# shearwater register map
Vendor: RedShift Labs; Series: IMU; File version: 0.3
Address unit: 32 bits
Registers are 32-bit, read-write, reset 0x0 unless marked. A register's access mark holds for its fields unless they carry their own. Offsets are from the block's base; [hi:lo] are bit positions; {n}, {i} and the like mark numbered series; 'fields as' and 'values as' point back to an identical list.

## MAIN_REGISTER_MAP — Fusion Configuration Registers for the shearwater board
Base 0x00000000
? CREG_COM_SETTINGS — The CREG_COM_SETTINGS register is used to set the boards serial port baud rate and to enable (disable) the automatic transmission of sensor data and estimated states (telemetry).
  [31:28] BAUD_RATE — Sets the baud rate of the boards main serial port:
    0=Baud rate: 9600; 1=Baud rate: 14400; 2=Baud rate: 19200; 3=Baud rate: 38400; 4=Baud rate: 57600; 5=Baud rate: 115200; 6=Baud rate: 128000; 7=Baud rate: 153600; 8=Baud rate: 230400; 9=Baud rate: 256000; 10=Baud rate: 460800; 11=Baud rate: 921600
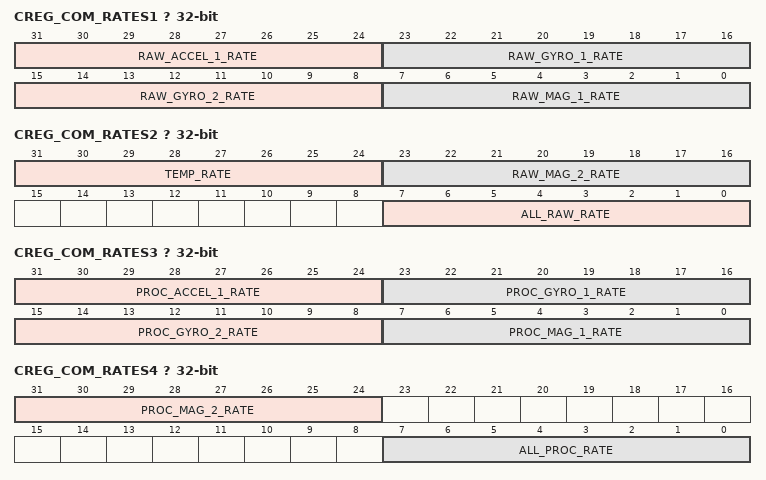
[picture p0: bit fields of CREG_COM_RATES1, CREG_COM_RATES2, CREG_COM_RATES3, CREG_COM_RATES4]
? CREG_COM_RATES1 — The CREG_COM_RATES1 register sets desired telemetry transmission rates in Hz for raw accelerometer 1, gyro 1, gyro 2 and magnetometer 1 data. If the specified rate is 0, then no data is transmitted.
  [31:24] RAW_ACCEL_1_RATE — Specifies the desired raw accelerometer 1 data broadcast rate in Hz. The data is stored as an unsigned 8-bit integer, yielding a maximum rate of 255 Hz.
  [23:16] RAW_GYRO_1_RATE — Specifies the desired raw gyro 1 data broadcast rate in Hz. The data is stored as an unsigned 8-bit integer, yielding a maximum rate of 255 Hz
  [15:8] RAW_GYRO_2_RATE — Specifies the desired raw gyro 2 data broadcast rate in Hz. The data is stored as an unsigned 8-bit integer, yielding a maximum rate of 255 Hz.
  [7:0] RAW_MAG_1_RATE — Specifies the desired raw magnetometer 1 data broadcast rate in Hz. The data is stored as an unsigned 8-bit integer, yielding a maximum rate of 255 Hz.
? CREG_COM_RATES2 — The CREG_COM_RATES2 register sets desired telemetry transmission rates for the magnetometer 2, all raw data, and temperature data rate. The ALL_RAW_RATE setting has higher priority over the individual raw sensor data settings, i.e. whenever this bitfield is set, then the individual raw sensor settings are ignored and not used. If the specified rate is 0, then no data is transmitted.
  [31:24] TEMP_RATE — Specifies the desired broadcast rate for temperature data. The data is stored as an unsigned 8-bit integer, yielding a maximum rate of 255 Hz.
  [23:16] RAW_MAG_2_RATE — Specifies the desired raw magnetometer 2 data broadcast rate in Hz. The data is stored as an unsigned 8-bit integer, yielding a maximum rate of 255 Hz.
  [7:0] ALL_RAW_RATE — Specifies the desired broadcast rate for all raw sensor data. If set, this overrides the broadcast rate setting for individual raw data broadcast rates. The data is stored as an unsigned 8-bit integer, yielding a maximum rate of 255 Hz.
? CREG_COM_RATES3 — The CREG_COM_RATES3 register sets desired telemetry transmission rates for processed sensor data for the sensors: the accelerometer 1, gyro 1, gyro 2, and magnetometer 1. If the specified rate is 0, then no data is transmitted.
  [31:24] PROC_ACCEL_1_RATE — Specifies the desired broadcast rate for processed accelerometer 1 data. The data is stored as an unsigned 8-bit integer, yielding a maximum rate of 255 Hz.
  [23:16] PROC_GYRO_1_RATE — Specifies the desired broadcast rate for processed rate gyro 1 data. The data is stored as an unsigned 8-bit integer, yielding a maximum rate of 255 Hz.
  [15:8] PROC_GYRO_2_RATE — Specifies the desired broadcast rate for processed processed rate gyro 2 data. The data is stored as an unsigned 8-bit integer, yielding a maximum rate of 255 Hz.
  [7:0] PROC_MAG_1_RATE — Specifies the desired broadcast rate for processed magnetometer 1 data. The data is stored as an unsigned 8-bit integer, yielding a maximum rate of 255 Hz.
? CREG_COM_RATES4 — The CREG_COM_RATES4 register defines the desired telemetry transmission rates for the processed data for the magnetometer 2, and for all processed data. The ALL_PROC_RATE setting has higher priority over the individual processed sensor data settings, i.e. whenever this bitfield is set, then the individual processed sensor transmission rate settings are ignored and not used. If the specified rate is 0, then no data is transmitted.
  [31:24] PROC_MAG_2_RATE — Specifies the desired broadcast rate for processed magnetometer 2 data. The data is stored as an unsigned 8-bit integer, yielding a maximum rate of 255 Hz.
  [7:0] ALL_PROC_RATE — Specifies the desired broadcast rate for raw all processed sensor data. If set, this overrides the broadcast rate setting for individual processed data broadcast rates. The data is stored as an unsigned 8-bit integer, yielding a maximum rate of 255 Hz.
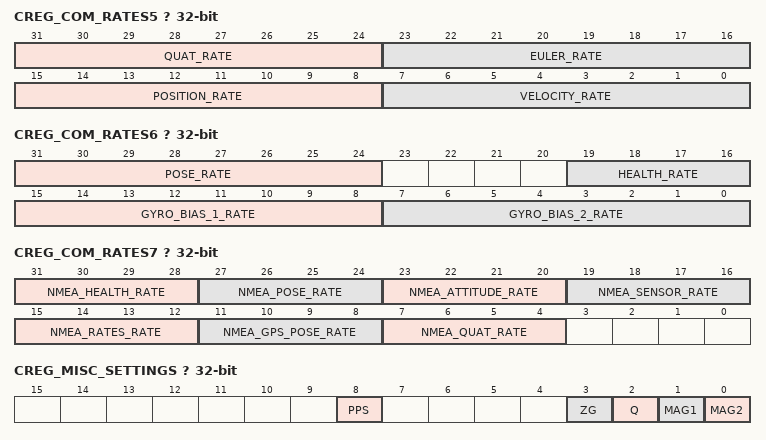
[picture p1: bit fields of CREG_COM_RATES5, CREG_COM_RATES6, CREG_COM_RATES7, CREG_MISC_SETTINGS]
? CREG_COM_RATES5 — The CREG_COM_RATES5 register sets desired telemetry transmission rates for quaternions, Euler Angles, position, and velocity estimates. If the specified rate is 0, then no data is transmitted.
  [31:24] QUAT_RATE — Specifies the desired broadcast rate for quaternion data. The data is stored as an unsigned 8-bit integer, yielding a maximum rate of 255 Hz.
  [23:16] EULER_RATE — Specifies the desired broadcast rate for Euler Angle data. The data is stored as an unsigned 8-bit integer, yielding a maximum rate of 255 Hz.
  [15:8] POSITION_RATE — Specifies the desired broadcast rate position. The data is stored as an unsigned 8-bit integer, yielding a maximum rate of 255 Hz.
  [7:0] VELOCITY_RATE — Specifies the desired broadcast rate for velocity. The data is stored as an unsigned 8-bit integer, yielding a maximum rate of 255 Hz.
? CREG_COM_RATES6 — The CREG_COM_RATES6 register sets desired telemetry transmission rates for pose (Euler/position packet), health, and gyro bias estimates for the gyro 1 and gyro 2. If the specified rate is 0, then no data is transmitted.
  [31:24] POSE_RATE — Specifies the desired broadcast rate for pose (Euler Angle and position) data. The data is stored as an unsigned 8-bit integer, yielding a maximum rate of 255 Hz.
  [19:16] HEALTH_RATE — Specifies the desired broadcast rate for the sensor health packet.
    0=Packet frequency: OFF; 1=0_125 (Packet frequency: 0.125 Hz); 2=0_25 (Packet frequency: 0.25 Hz); 3=0_5 (Packet frequency: 0.5 Hz); 4=Packet frequency: 1 Hz; 5=Packet frequency: 2 Hz; 6=Packet frequency: 4 Hz
  [15:8] GYRO_BIAS_1_RATE — Specifies the desired broadcast rate for gyro 1 bias estimates. The data is stored as an unsigned 8-bit integer, yielding a maximum rate of 255 Hz.
  [7:0] GYRO_BIAS_2_RATE — Specifies the desired broadcast rate for gyro 2 bias estimates. The data is stored as an unsigned 8-bit integer, yielding a maximum rate of 255 Hz.
? CREG_COM_RATES7 — The CREG_COM_RATES7 register sets desired telemetry transmission rates in Hz for NMEA packets.
  [all] fields
    0=Packet frequency: OFF; 1=Packet frequency: 1 Hz; 2=Packet frequency: 2 Hz; 3=Packet frequency: 4 Hz; 4=Packet frequency: 5 Hz; 5=Packet frequency: 10 Hz; 6=Packet frequency: 15 Hz; 7=Packet frequency: 20 Hz; 8=Packet frequency: 30 Hz; 9=Packet frequency: 40 Hz; 10=Packet frequency: 50 Hz; 11=Packet frequency: 60 Hz; 12=Packet frequency: 70 Hz; 13=Packet frequency: 80 Hz; 14=Packet frequency: 90 Hz; 15=Packet frequency: 100 Hz
  [31:28] NMEA_HEALTH_RATE — Specifies the desired broadcast rate for Redshift Labs NMEA-style health packet.
  [27:24] NMEA_POSE_RATE — Specifies the desired broadcast rate for Redshift Labs NMEA-style pose (Euler Angle/position) packet.
  [23:20] NMEA_ATTITUDE_RATE — Specifies the desired broadcast rate for Redshift Labs NMEA-style attitude packet.
  [19:16] NMEA_SENSOR_RATE — Specifies the desired broadcast rate for Redshift Labs NMEA-style sensor data packet.
  [15:12] NMEA_RATES_RATE — Specifies the desired broadcast rate for Redshift Labs NMEA-style rate data packet.
  [11:8] NMEA_GPS_POSE_RATE — Specifies the desired broadcast rate for Redshift Labs NMEA-style GPS pose packet.
  [7:4] NMEA_QUAT_RATE — Specifies the desired broadcast rate for Redshift Labs NMEA-style quaternion packet.
? CREG_MISC_SETTINGS — This register contains miscellaneous filter and sensor control options.
  [8] PPS — If set, this bit causes the TX2 pin on the IO Expansion header to be used as the PPS input from an external GPS module. PPS pulses will then be used to synchronize the system clock to UTC time of day.
    0=PPS_OFF (TX2 not used as PPS input from GPS); 1=PPS_ON (TX2 used as PPS input from GPS)
  [3] ZG — If set, this bit causes the devicee to attempt to measure the rate gyro bias on startup. The sensor must be stationary on startup for this feature to work properly.
    0=ZG_OFF (NOT measure rate gyro bias on startup); 1=ZG_ON (Measure rate gyro bias on startup)
  [2] Q — If this bit is set, the sensor will run in quaternion mode instead of Euler Angle mode.
    0=EULER_MODE (The sensor will run in Euler Angle mode); 1=QUATERNION_MODE (The sensor will run in quaternion mode)
  [1] MAG1 — If set, the magnetometer 1 will be used in state updates.
    0=MAG1_NOT_IN_STATE (NOT use magnetometer 1 in state update); 1=MAG1_IN_STATE (Use magnetometer 1 in state update)
  [0] MAG2 — If set, the magnetometer 2 will be used in state updates.
    0=MAG2_NOT_IN_STATE (NOT use magnetometer 2 in state update); 1=MAG2_IN_STATE (Use magnetometer 2 in state update)
? CREG_GYRO_1_MEAS_RANGE — The CREG_GYRO_1_MEAS_RANGE register sets the desired measurement range for the gyro 1 sensor. If the rate is not set, then the default value of 2000 deg/s will be used as a measurement range.
  [1:0] MEAS_GYRO1 — Specifies the desired measurement range for the gyro 1 measurements.
    0=2000_dps (Measurement range: +- 2000 dps); 1=1000_dps (Measurement range: +- 1000 dps); 2=500_dps (Measurement range: +- 500 dps); 3=250_dps (Measurement range: +- 250 dps)
? CREG_GYRO_1_TRIM_X — This register sets the x-axis rate gyro 1 trim, which is used to add additional bias compensation for the rate gyros during calls to the ZERO_GYRO_BIAS command.
  [31:0] GYRO_1_TRIM_X — 32-bit IEEE Floating Point Value
? CREG_GYRO_1_TRIM_Y — This register sets the y-axis rate gyro 1 trim, which is used to add additional bias compensation for the rate gyros during calls to the ZERO_GYRO_BIAS command.
  [31:0] GYRO_1_TRIM_Y — 32-bit IEEE Floating Point Value
? CREG_GYRO_1_TRIM_Z — This register sets the z-axis rate gyro 1 trim, which is used to add additional bias compensation for the rate gyros during calls to the ZERO_GYRO_BIAS command.
  [31:0] GYRO_1_TRIM_Z — 32-bit IEEE Floating Point Value
? CREG_GYRO_2_MEAS_RANGE — The CREG_GYRO_2_MEAS_RANGE register sets the desired measurement range for the gyro 2 sensor. If the rate is not set, then the default value of 2000 deg/s will be used as a measurement range.
  [1:0] MEAS_GYRO2 — Specifies the desired measurement range for the gyro 2 measurements.
    values as CREG_GYRO_1_MEAS_RANGE.MEAS_GYRO1
? CREG_GYRO_2_TRIM_X — This register sets the x-axis rate gyro 2 trim, which is used to add additional bias compensation for the rate gyros during calls to the ZERO_GYRO_BIAS command.
  [31:0] GYRO_2_TRIM_X — 32-bit IEEE Floating Point Value
? CREG_GYRO_2_TRIM_Y — This register sets the y-axis rate gyro 2 trim, which is used to add additional bias compensation for the rate gyros during calls to the ZERO_GYRO_BIAS command.
  [31:0] GYRO_2_TRIM_Y — 32-bit IEEE Floating Point Value
? CREG_GYRO_2_TRIM_Z — This register sets the z-axis rate gyro 2 trim, which is used to add additional bias compensation for the rate gyros during calls to the ZERO_GYRO_BIAS command.
  [31:0] GYRO_2_TRIM_Z — 32-bit IEEE Floating Point Value
? CREG_MAG_1_CAL{i}_1 (i=1..3) — Row {i}, Column 1 of magnetometer 1 calibration matrix.
  [31:0] MAG_1_CAL{i}_1 — 32-bit IEEE Floating Point Value
? CREG_MAG_1_CAL{i}_2 (i=1..3) — Row {i}, Column 2 of magnetometer 1 calibration matrix.
  [31:0] MAG_1_CAL{i}_2 — 32-bit IEEE Floating Point Value
? CREG_MAG_1_CAL{i}_3 (i=1..3) — Row {i}, Column 3 of magnetometer 1 calibration matrix.
  [31:0] MAG_1_CAL{i}_3 — 32-bit IEEE Floating Point Value
? CREG_MAG_1_BIAS_X — This register stores a bias term for the magnetometer 1 x-axis for hard-iron calibration. This term can be computed by performing magnetometer calibration with the Redshift labs Serial Interface.
  [31:0] MAG_1_BIAS_X — 32-bit IEEE Floating Point Value
? CREG_MAG_1_BIAS_Y — This register stores a bias term for the magnetometer 1 y-axis for hard-iron calibration. This term can be computed by performing magnetometer calibration with the Redshift labs Serial Interface.
  [31:0] MAG_1_BIAS_Y — 32-bit IEEE Floating Point Value
? CREG_MAG_1_BIAS_Z — This register stores a bias term for the magnetometer 1 z-axis for hard-iron calibration. This term can be computed by performing magnetometer calibration with the Redshift labs Serial Interface.
  [31:0] MAG_1_BIAS_Z — 32-bit IEEE Floating Point Value
? CREG_MAG_2_CAL{i}_1 (i=1..3) — Row {i}, Column 1 of magnetometer 2 calibration matrix.
  [31:0] MAG_2_CAL{i}_1 — 32-bit IEEE Floating Point Value
? CREG_MAG_2_CAL{i}_2 (i=1..3) — Row {i}, Column 2 of magnetometer 2 calibration matrix.
  [31:0] MAG_2_CAL{i}_2 — 32-bit IEEE Floating Point Value
? CREG_MAG_2_CAL{i}_3 (i=1..3) — Row {i}, Column 3 of magnetometer 2 calibration matrix.
  [31:0] MAG_2_CAL{i}_3 — 32-bit IEEE Floating Point Value
? CREG_MAG_2_BIAS_X — This register stores a bias term for the magnetometer 2 x-axis for hard-iron calibration. This term can be computed by performing magnetometer calibration with the Redshift labs Serial Interface.
  [31:0] MAG_2_BIAS_X — 32-bit IEEE Floating Point Value
? CREG_MAG_2_BIAS_Y — This register stores a bias term for the magnetometer 2 y-axis for hard-iron calibration. This term can be computed by performing magnetometer calibration with the Redshift labs Serial Interface.
  [31:0] MAG_2_BIAS_Y — 32-bit IEEE Floating Point Value
? CREG_MAG_2_BIAS_Z — This register stores a bias term for the magnetometer 2 z-axis for hard-iron calibration. This term can be computed by performing magnetometer calibration with the Redshift labs Serial Interface.
  [31:0] MAG_2_BIAS_Z — 32-bit IEEE Floating Point Value
? CREG_ACCEL_1_MEAS_RANGE — The CREG_ACCEL_1_MEAS_RANGE register sets the desired measurement range for the accelerometer 1. If the rate is not set, then the default value of the +-2 g will be used as a measurement range.
  [1:0] MEAS_ACC1 — Specifies the desired measurement range for the accelerometer 1 measurements.
    0=2_g (Measurement range: +- 2 g); 1=4_g (Measurement range: +- 4 g); 2=8_g (Measurement range: +- 8 g); 3=16_g (Measurement range: +- 16 g)
? CREG_ACCEL_1_CAL{i}_1 (i=1..3) — Row {i}, Column 1 of accelerometer 1 calibration matrix.
  [31:0] ACCEL_1_CAL{i}_1 — 32-bit IEEE Floating Point Value
? CREG_ACCEL_1_CAL{i}_2 (i=1..3) — Row {i}, Column 2 of accelerometer 1 calibration matrix.
  [31:0] ACCEL_1_CAL{i}_2 — 32-bit IEEE Floating Point Value
? CREG_ACCEL_1_CAL{i}_3 (i=1..3) — Row {i}, Column 3 of accelerometer 1 calibration matrix.
  [31:0] ACCEL_1_CAL{i}_3 — 32-bit IEEE Floating Point Value
? CREG_ACCEL_1_BIAS_X — This register stores a bias term for the accelerometer 1 x-axis for bias calibration. This term can be computed by performing calibrate accelerometers command within the Redshift labs Serial Interface.
  [31:0] ACCEL_1_BIAS_X — 32-bit IEEE Floating Point Value
? CREG_ACCEL_1_BIAS_Y — This register stores a bias term for the accelerometer 1 y-axis for bias calibration. This term can be computed by performing calibrate accelerometers command within the Redshift labs Serial Interface.
  [31:0] ACCEL_1_BIAS_Y — 32-bit IEEE Floating Point Value
? CREG_ACCEL_1_BIAS_Z — This register stores a bias term for the accelerometer 1 z-axis for bias calibration. This term can be computed by performing calibrate accelerometers command within the Redshift labs Serial Interface.
  [31:0] ACCEL_1_BIAS_Z — 32-bit IEEE Floating Point Value
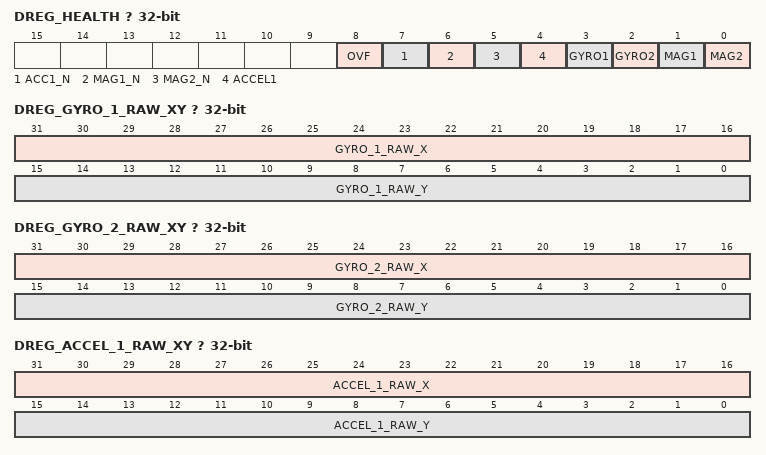
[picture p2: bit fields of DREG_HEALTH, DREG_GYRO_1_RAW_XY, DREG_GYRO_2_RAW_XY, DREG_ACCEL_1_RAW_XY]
? DREG_HEALTH ro — The health register reports the current status of the sensors on the board. Monitoring the health register is the easiest way to watch for other problems that could affect the behavior of the board, status of the sensors. The analogous to the health register, the status of the GPS signal can be monitored in the DREG_GPS_HEALTH
  [8] OVF — Overflow bit. This bit is set if the board is attempting to transmit data over the serial port faster than is allowed given the baud-rate. If this bit is set, reduce broadcast rates in the COM_RATES registers.
    0=OVF_OFF (No overflow registered); 1=OVF_ON (Overflow registered, reduce broadcast rates)
  [7] ACC1_N — This bit is set if the sensor detects that the norm of the accelerometer measurement is too far away from 1G to be used (i.e. during aggressive acceleration or high vibration).
    0=ACC1_N_OFF (No high acceleration / no high vibration detected); 1=ACC1_N_ON (High acceleration / high vibration detected)
  [6] MAG1_N — This bit is set if the sensor detects that the norm of the magnetometer measurement for the magnetometer 1 is too far away from 1.0 to be trusted. Usually indicates bad calibration, local field distortions, or both.
    0=MAG2_NORM_OK (Magnetometer 1 norm is OK); 1=MAG2_NORM_WARN (Magnetometer 1 norm is not OK)
  [5] MAG2_N — This bit is set if the sensor detects that the norm of the magnetometer measurement for the magnetometer 2 is too far away from 1.0 to be trusted. Usually indicates bad calibration, local field distortions, or both.
    0=MAG2_NORM_OK (Magnetometer 2 norm is OK); 1=MAG2_NORM_WARN (Magnetometer 2 norm is not OK)
  [4] ACCEL1 — This bit will be set if the accelerometer 1 fails to initialize on startup.
    0=ACCEL1_STARTUP_OK (Accelerometer 1 startup OK); 1=ACCEL1_STARTUP_ERR (Accelerometer 1 startup error)
  [3] GYRO1 — This bit will be set if the rate gyro 1 fails to initialize on startup.
    0=GYRO1_STARTUP_OK; 1=GYRO1_STARTUP_ERR (Gyro 1 startup error)
  [2] GYRO2 — This bit will be set if the rate gyro 2 fails to initialize on startup.
    0=GYRO2_STARTUP_OK; 1=GYRO2_STARTUP_ERR (Gyro 2 startup error)
  [1] MAG1 — This bit will be set if the magnetometer 1 fails to initialize on startup.
    0=MAG1_STARTUP_OK (Magnetometer 1 startup OK); 1=MAG1_STARTUP_ERR (Magnetometer 1 startup error)
  [0] MAG2 — This bit will be set if the magnetometer 2 fails to initialize on startup.
    0=MAG2_STARTUP_OK (Magnetometer 2 startup OK); 1=MAG2_STARTUP_ERR (Magnetometer 2 startup error)
? DREG_GYRO_1_RAW_XY ro — Contains raw X and Y axis rate gyro 1 data.
  [31:16] GYRO_1_RAW_X — Gyro X (2s complement 16-bit integer)
  [15:0] GYRO_1_RAW_Y — Gyro Y (2s complement 16-bit integer)
? DREG_GYRO_1_RAW_Z ro — Contains raw Z axis rate gyro 1 data.
  [31:16] GYRO_1_RAW_Z — Gyro Z (2s complement 16-bit integer)
? DREG_GYRO_1_RAW_TIME ro — Contains time at which the last rate gyro 1 data was acquired.
  [31:0] GYRO_1_RAW_TIME — 32-bit IEEE Floating Point Value
? DREG_GYRO_2_RAW_XY ro — Contains raw X and Y axis rate gyro 2 data.
  [31:16] GYRO_2_RAW_X — Gyro X (2s complement 16-bit integer)
  [15:0] GYRO_2_RAW_Y — Gyro Y (2s complement 16-bit integer)
? DREG_GYRO_2_RAW_Z ro — Contains raw Z axis rate gyro 2 data.
  [31:16] GYRO_2_RAW_Z — Gyro Z (2s complement 16-bit integer)
? DREG_GYRO_2_RAW_TIME ro — Contains time at which the last rate gyro 2 data was acquired.
  [31:0] GYRO_2_RAW_TIME — 32-bit IEEE Floating Point Value
? DREG_ACCEL_1_RAW_XY ro — Contains raw X and Y axis accelerometer 1 data.
  [31:16] ACCEL_1_RAW_X — Accel X (2s complement 16-bit integer)
  [15:0] ACCEL_1_RAW_Y — Accel Y (2s complement 16-bit integer)
? DREG_ACCEL_1_RAW_Z ro — Contains raw Z axis accelerometer 1 data.
  [31:16] ACCEL_1_RAW_Z — Accel Z (2s complement 16-bit integer)
? DREG_ACCEL_1_RAW_TIME ro — Contains time at which the last raw data sample for the accelerometer 1 was acquired.
  [31:0] ACCEL_1_RAW_TIME — 32-bit IEEE Floating Point Value
? DREG_MAG_1_RAW_X ro — Contains raw x axis magnetometer 1 data.
  [31:0] MAG_1_RAW_X — 32-bit signed integer value
? DREG_MAG_1_RAW_Y ro — Contains raw y axis magnetometer 1 data.
  [31:0] MAG_1_RAW_Y — 32-bit signed integer value
? DREG_MAG_1_RAW_Z ro — Contains raw z axis magnetometer 1 data.
  [31:0] MAG_1_RAW_Z — 32-bit signed integer value
? DREG_MAG_1_RAW_TIME ro — Contains time at which the last magnetometer data from the magnetometer 1 was acquired.
  [31:0] MAG_1_RAW_TIME — 32-bit IEEE Floating Point Value
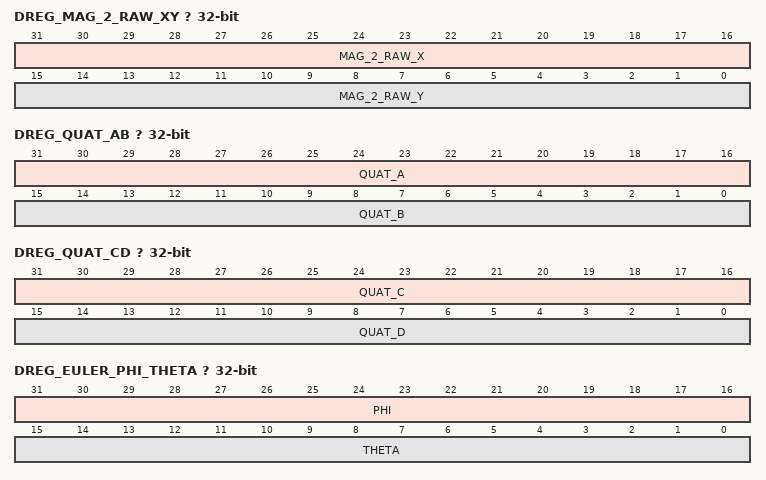
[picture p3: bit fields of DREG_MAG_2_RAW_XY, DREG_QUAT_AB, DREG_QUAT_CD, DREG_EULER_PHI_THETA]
? DREG_MAG_2_RAW_XY ro — Contains raw X and Y axis magnetometer 2 data.
  [31:16] MAG_2_RAW_X — Magnetometer X (2s complement 16-bit integer)
  [15:0] MAG_2_RAW_Y — Magnetometer Y (2s complement 16-bit integer)
? DREG_MAG_2_RAW_Z ro — Contains raw Z axis magnetometer 2 data.
  [31:16] MAG_2_RAW_Z — Magnetometer Z (2s complement 16-bit integer)
? DREG_MAG_2_RAW_TIME ro — Contains time at which the last magnetometer data from the magnetometer 2 was acquired.
  [31:0] MAG_2_RAW_TIME — 32-bit IEEE Floating Point Value
? DREG_TEMPERATURE ro — Contains the temperature output of the onboard temperature sensor.
  [31:0] TEMPERATURE — Temperature in degrees Celcius (32-bit IEEE Floating Point)
? DREG_TEMPERATURE_TIME ro — Contains time at which the last temperature was acquired.
  [31:0] TEMPERATURE_TIME — 32-bit IEEE Floating Point Value
? DREG_GYRO_1_PROC_X ro — Contains the actual measured angular rate from the gyro 1 for the x axis in degrees/sec after calibration has been applied.
  [31:0] GYRO_1_PROC_X — Gyro X in degrees / sec (32-bit IEEE Floating Point Value)
? DREG_GYRO_1_PROC_Y ro — Contains the actual measured angular rate from the gyro 1 for the y axis in degrees/sec after calibration has been applied.
  [31:0] GYRO_1_PROC_Y — Gyro Y in degrees / sec (32-bit IEEE Floating Point Value)
? DREG_GYRO_1_PROC_Z ro — Contains the actual measured angular rate from the gyro 1 for the z axis in degrees/sec after calibration has been applied.
  [31:0] GYRO_1_PROC_Z — Gyro Z in degrees / sec (32-bit IEEE Floating Point Value)
? DREG_GYRO_1_PROC_TIME ro — Contains the time at which the last rate gyro data from the gyro 1 was measured.
  [31:0] GYRO_1_PROC_TIME — Gyro 1 time stamp (32-bit IEEE Floating Point Value)
? DREG_GYRO_2_PROC_X ro — Contains the actual measured angular rate from the gyro 2 for the x axis in degrees/sec after calibration has been applied.
  [31:0] GYRO_2_PROC_X — Gyro X in degrees / sec (32-bit IEEE Floating Point Value)
? DREG_GYRO_2_PROC_Y ro — Contains the actual measured angular rate from the gyro 2 for the y axis in degrees/sec after calibration has been applied.
  [31:0] GYRO_2_PROC_Y — Gyro Y in degrees / sec (32-bit IEEE Floating Point Value)
? DREG_GYRO_2_PROC_Z ro — Contains the actual measured angular rate from the gyro 2 for the z axis in degrees/sec after calibration has been applied.
  [31:0] GYRO_2_PROC_Z — Gyro Z in degrees / sec (32-bit IEEE Floating Point Value)
? DREG_GYRO_2_PROC_TIME ro — Contains the time at which the last rate gyro data from the gyro 2 was measured.
  [31:0] GYRO_2_PROC_TIME — Gyro 2 time stamp (32-bit IEEE Floating Point Value)
? DREG_ACCEL_1_PROC_X ro — Contains the actual measured acceleration from the accelerometer 1 for the x axis in m/s2 after calibration has been applied.
  [31:0] ACCEL_1_PROC_X — Acceleration X in m/s2 (32-bit IEEE Floating Point Value)
? DREG_ACCEL_1_PROC_Y ro — Contains the actual measured acceleration from the accelerometer 1 for the y axis in m/s2 after calibration has been applied.
  [31:0] ACCEL_1_PROC_Y — Acceleration Y in m/s2 (32-bit IEEE Floating Point Value)
? DREG_ACCEL_1_PROC_Z ro — Contains the actual measured acceleration from the accelerometer 1 for the z axis in m/s2 after calibration has been applied.
  [31:0] ACCEL_1_PROC_Z — Acceleration Z in m/s2 (32-bit IEEE Floating Point Value)
? DREG_ACCEL_1_PROC_TIME ro — Contains the time at which the last acceleration data from the accelerometer 1 was measured.
  [31:0] ACCEL_1_PROC_TIME — Accelerometer 1 time stamp (32-bit IEEE Floating Point Value)
? DREG_MAG_1_PROC_X ro — Contains the actual measured magnetic field from the magnetometer 1 for the x axis in mT after calibration has been applied.
  [31:0] MAG_1_PROC_X — Magnetometer X in mT (32-bit IEEE Floating Point Value)
? DREG_MAG_1_PROC_Y ro — Contains the actual measured magnetic field from the magnetometer 1 for the y axis in mT after calibration has been applied.
  [31:0] MAG_1_PROC_Y — Magnetometer Y in mT (32-bit IEEE Floating Point Value)
? DREG_MAG_1_PROC_Z ro — Contains the actual measured magnetic field from the magnetometer 1 for the z axis in mT after calibration has been applied.
  [31:0] MAG_1_PROC_Z — Magnetometer Z in mT (32-bit IEEE Floating Point Value)
? DREG_MAG_1_NORM ro — Contains the L2-norm (magnetic norm) for the measured magnetic field from the magnetometer 1 computed over the calibrated values.
  [31:0] MAG_1_NORM — Magnetic norm (32-bit IEEE Floating Point Value)
? DREG_MAG_1_PROC_TIME ro — Contains the time stamp at which the calibrated magnetometer 1 data was acquired.
  [31:0] MAG_1_PROC_TIME — Magnetometer 1 time stamp (32-bit IEEE Floating Point Value)
? DREG_MAG_2_PROC_X ro — Contains the actual measured magnetic field from the magnetometer 2 for the x axis in mT after calibration has been applied.
  [31:0] MAG_2_PROC_X — Magnetometer X in mT (32-bit IEEE Floating Point Value)
? DREG_MAG_2_PROC_Y ro — Contains the actual measured magnetic field from the magnetometer 2 for the y axis in mT after calibration has been applied.
  [31:0] MAG_2_PROC_Y — Magnetometer Y in mT (32-bit IEEE Floating Point Value)
? DREG_MAG_2_PROC_Z ro — Contains the actual measured magnetic field from the magnetometer 2 for the z axis in mT after calibration has been applied.
  [31:0] MAG_2_PROC_Z — Magnetometer Z in mT (32-bit IEEE Floating Point Value)
? DREG_MAG_2_NORM ro — Contains the L2-norm (magnetic norm) for the measured magnetic field from the magnetometer 2 computed over the calibrated values.
  [31:0] MAG_2_NORM — Magnetic norm (32-bit IEEE Floating Point Value)
? DREG_MAG_2_PROC_TIME ro — Contains the time stamp at which the calibrated magnetometer 2 data was acquired.
  [31:0] MAG_2_PROC_TIME — Magnetometer 2 time stamp (32-bit IEEE Floating Point Value)
? DREG_QUAT_AB ro — Contains the first two components (a and b) of the estimated quaternion attitude.
  [31:16] QUAT_A — First quaternion component. Stored as a 16-bit signed integer. To get the actual value, divide by 29789.09091.
  [15:0] QUAT_B — Second quaternion component. Stored as a 16-bit signed integer. To get the actual value, divide by 29789.09091.
? DREG_QUAT_CD ro — Contains the second two components (c and d) of the estimated quaternion attitude.
  [31:16] QUAT_C — Third quaternion component. Stored as a 16-bit signed integer. To get the actual value, divide by 29789.09091.
  [15:0] QUAT_D — Fourth quaternion component. Stored as a 16-bit signed integer. To get the actual value, divide by 29789.09091.
? DREG_QUAT_TIME ro — Contains the time that the quaternion attitude was estimated.
  [31:0] QUAT_TIME — Quaternion time (32-bit IEEE Floating Point Value)
? DREG_EULER_PHI_THETA ro — Contains the pitch and roll angle estimates.
  [31:16] PHI — Roll angle. Stored as a 16-bit signed integer. To get the actual value, divide by 91.02222.
  [15:0] THETA — Pitch angle. Stored as a 16-bit signed integer. To get the actual value, divide by 91.02222.
? DREG_EULER_PSI ro — Contains the yaw angle estimate.
  [31:16] PSI — Yaw angle. Stored as a 16-bit signed integer. To get the actual value, divide by 91.02222.
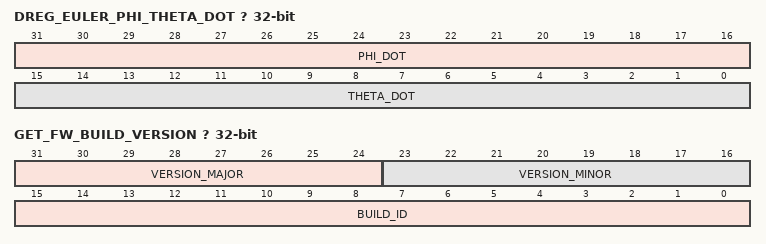
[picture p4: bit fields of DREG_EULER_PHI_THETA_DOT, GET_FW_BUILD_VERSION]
? DREG_EULER_PHI_THETA_DOT ro — Contains the pitch and roll rate estimates.
  [31:16] PHI_DOT — Roll rate. Stored as a 16-bit signed integer. To get the actual value, divide by 16.0.
  [15:0] THETA_DOT — Pitch rate. Stored as a 16-bit signed integer. To get the actual value, divide by 16.0.
? DREG_EULER_PSI_DOT ro — Contains the yaw rate estimate.
  [31:16] PSI_DOT — Yaw rate. Stored as a 16-bit signed integer. To get the actual value, divide by 16.0.
? DREG_EULER_TIME ro — Contains the time that the Euler Angles were estimated.
  [31:0] EULER_TIME — Euler time (32-bit IEEE Floating Point Value)
? DREG_POSITION_NORTH ro — Contains the measured north position in meters from the latitude specified in CREG_HOME_NORTH.
  [31:0] POSITION_NORTH — North Position (32-bit IEEE Floating Point Value)
? DREG_POSITION_EAST ro — Contains the measured east position in meters from the longitude specified in CREG_HOME_EAST.
  [31:0] POSITION_EAST — East Position (32-bit IEEE Floating Point Value)
? DREG_POSITION_UP ro — Contains the measured altitude in meters from the altitude specified in CREG_HOME_UP.
  [31:0] POSITION_UP — Altitude (32-bit IEEE Floating Point Value)
? DREG_POSITION_TIME ro — Contains the time at which the position was acquired.
  [31:0] POSITION_TIME — Position Time (32-bit IEEE Floating Point Value)
? DREG_VELOCITY_NORTH ro — Contains the measured north velocity in m/s.
  [31:0] VELOCITY_NORTH — North Velocity (32-bit IEEE Floating Point Value)
? DREG_VELOCITY_EAST ro — Contains the measured east velocity in m/s.
  [31:0] VELOCITY_EAST — East Velocity (32-bit IEEE Floating Point Value)
? DREG_VELOCITY_UP ro — Contains the measured altitude velocity in m/s.
  [31:0] VELOCITY_UP — Altitude Velocity (32-bit IEEE Floating Point Value)
? DREG_VELOCITY_TIME ro — Contains the time at which the velocity was measured.
  [31:0] VELOCITY_TIME — Velocity time (32-bit IEEE Floating Point Value)
? DREG_GYRO_1_BIAS_X ro — Contains the estimated x-axis bias for the gyro 1 in degrees/s.
  [31:0] GYRO_1_BIAS_X — Gyro 1 bias X (32-bit IEEE Floating Point Value)
? DREG_GYRO_1_BIAS_Y ro — Contains the estimated y-axis bias for the gyro 1 in degrees/s.
  [31:0] GYRO_1_BIAS_Y — Gyro 1 bias Y (32-bit IEEE Floating Point Value)
? DREG_GYRO_1_BIAS_Z ro — Contains the estimated z-axis bias for the gyro 1 in degrees/s.
  [31:0] GYRO_1_BIAS_Z — Gyro 1 bias Z (32-bit IEEE Floating Point Value)
? DREG_GYRO_2_BIAS_X ro — Contains the estimated x-axis bias for the gyro 2 in degrees/s.
  [31:0] GYRO_2_BIAS_X — Gyro 2 bias X (32-bit IEEE Floating Point Value)
? DREG_GYRO_2_BIAS_Y ro — Contains the estimated y-axis bias for the gyro 2 in degrees/s.
  [31:0] GYRO_2_BIAS_Y — Gyro 2 bias Y (32-bit IEEE Floating Point Value)
? DREG_GYRO_2_BIAS_Z ro — Contains the estimated z-axis bias for the gyro 2 in degrees/s.
  [31:0] GYRO_2_BIAS_Z — Gyro 2 bias Z (32-bit IEEE Floating Point Value)
? GET_FW_BUILD_ID ro — Firmware build identification string: a four byte ASCII character sequence which corresponds to a firmware series.
  [31:0] FW_BUILD_ID — Firmware Build ID string
? GET_FW_BUILD_VERSION ro — Firmware build version provides the unique identifier of the firmware programmed in the board. A response is four bytes long and identifies major and minor build version, and the build number.
  [31:24] VERSION_MAJOR — 8-bit unsigned integer major version number
  [23:16] VERSION_MINOR — 8-bit unsigned integer minor version number
  [15:0] BUILD_ID — 16-bit unsigned integer build ID number
? FLASH_COMMIT wo — Causes the board to write all configuration settings to FLASH so that are stored in the non-volatile memory and remain when the power is cycled.
  [1:0] FLASH_COMMIT_BIT
? RESET_TO_FACTORY wo — Causes the board to load default factory settings.
  [1:0] RESET_TO_FACTORY_BIT
? ZERO_GYROS wo — Causes the board to measure the gyro outputs and set the output trim registers to compensate for any non-zero bias. The board should be kept stationary while the zero operation is underway.
  [1:0] ZERO_GYROS_BIT
? SET_HOME_POSITION wo — Sets the current GPS latitude, longitude, and altitude as the home position. All future positions will be referenced to the current GPS position.
  [1:0] SET_HOME_POSITION_BIT
? SET_MAG_REFERENCE wo — Sets the current yaw heading position as north.
  [1:0] SET_MAG_REFERENCE_BIT — Set magnetometer reference bit
? CALIBRATE_ACCELEROMETERS wo — Reboots the board and performs a crude calibration on the accelerometers. Best performed on a flat surface.
  [1:0] CALIBRATE_ACCELEROMETERS_BIT
? RESET_FUSION wo — Resets the sensor fusion algorithm.
  [1:0] RESET_FUSION_BIT
? ENABLE_ZUPT wo — Enable zero velocity update.
  [1:0] ENABLE_ZUPT_BIT — Enable zero velocity update bit
? EULER_MODE wo — Enable as fusion output Euler angles only.
  [1:0] EULER_MODE_BIT — Fusion Euler mode bit
? QUATERNION_MODE wo — Enable as fusion output orientation quaternion only.
  [1:0] QUATERNION_MODE_BIT — Fusion quaternion mode bit
? ENABLE_RT_CALIBRATION wo — Starts RT calibration of the board.
  [1:0] ENABLE_RT_CALIBRATION_BIT — RT calibration bit
? EN_MAG_ANOMALY_DETECTION wo — Enables algorithm for anomaly detection.
  [1:0] EN_MAG_ANOMALY_DETECTION_BIT — Magnetic field anomaly detection bit
? RUN_SELF_TESTS wo — Starts built-in self tests.
  [1:0] RUN_SELF_TESTS_BIT
? ENABLE_EXTERNAL_EVENT wo — TODO: add description
  [1:0] ENABLE_EXTERNAL_EVENT_BIT
? ENABLE_GNNS_FUSION wo — TODO: add description
  [1:0] ENABLE_GNNS_FUSION_BIT — Enable GNSS fusion bit
? ENABLE_USR_EULER_OUTPUT wo — TODO: add description
  [1:0] ENABLE_USR_EULER_OUTPUT_BIT — Enable user Euler output bit
? ENABLE_DEAD_RECKONING wo — TODO: add description
  [1:0] ENABLE_DEAD_RECKONING_BIT
? ENABLE_HEAVE_SWAY_SURGE wo — TODO: add description
  [1:0] ENABLE_HEAVE_SWAY_SURGE_BIT
? ENABLE_UKF wo — TODO: add description
  [1:0] ENABLE_UKF_BIT
? BOARD_UNIQUE_ID_1 ro — First 32-bits of the 64-bits of the board unique identifier. Bits of the unique identifier cannot be modified by the user.
  [31:0] BOARD_UNIQUE_ID_1_BITS — Board unique ID bits
? BOARD_UNIQUE_ID_2 ro — Last 32-bits of the 64-bits of the board unique identifier. Bits of the unique identifier cannot be modified by the user.
  [31:0] BOARD_UNIQUE_ID_2_BITS — Board unique ID bits
? PROTOCOL_VERSION ro — String version of the protocol.
  [31:0] PROTOCOL_VERSION_STR — Protocol version string
